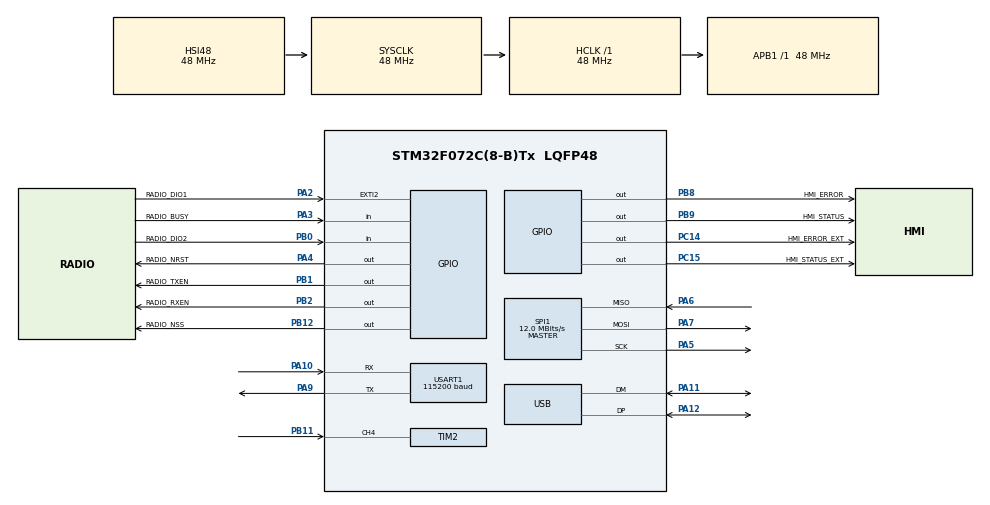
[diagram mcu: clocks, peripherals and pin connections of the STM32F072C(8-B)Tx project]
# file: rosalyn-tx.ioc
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Mcu.Family=STM32F0
Mcu.Name=STM32F072C(8-B)Tx
Mcu.Package=LQFP48
NVIC.EXTI2_3_IRQn=true\:0\:0\:false\:false\:true\:true\:true
NVIC.TIM2_IRQn=true\:0\:0\:false\:false\:true\:true\:true
NVIC.USB_IRQn=true\:0\:0\:false\:false\:true\:false\:true
PA10.GPIO_PuPd=GPIO_PULLUP
PA10.Mode=Asynchronous
PA10.Signal=USART1_RX
PA11.Mode=Device
PA11.Signal=USB_DM
PA12.Mode=Device
PA12.Signal=USB_DP
PA13.Mode=Serial_Wire
PA13.Signal=SYS_SWDIO
PA14.Mode=Serial_Wire
PA14.Signal=SYS_SWCLK
PA2.GPIO_Label=RADIO_DIO1
PA2.Signal=GPXTI2
PA3.GPIO_Label=RADIO_BUSY
PA3.Signal=GPIO_Input
PA4.GPIO_Label=RADIO_NRST
PA4.PinState=GPIO_PIN_SET
PA4.Signal=GPIO_Output
PA5.Mode=Full_Duplex_Master
PA5.Signal=SPI1_SCK
PA6.GPIO_PuPd=GPIO_PULLUP
PA6.Mode=Full_Duplex_Master
PA6.Signal=SPI1_MISO
PA7.Mode=Full_Duplex_Master
PA7.Signal=SPI1_MOSI
PA9.Mode=Asynchronous
PA9.Signal=USART1_TX
PB0.GPIO_Label=RADIO_DIO2
PB0.Signal=GPIO_Input
PB1.GPIO_Label=RADIO_TXEN
PB1.Signal=GPIO_Output
PB11.GPIO_ModeDefaultPP=GPIO_MODE_AF_PP
PB11.Signal=S_TIM2_CH4
PB12.GPIO_Label=RADIO_NSS
PB12.PinState=GPIO_PIN_SET
PB12.Signal=GPIO_Output
PB2.GPIO_Label=RADIO_RXEN
PB2.Signal=GPIO_Output
PB8.GPIO_Label=HMI_ERROR
PB8.PinState=GPIO_PIN_SET
PB8.Signal=GPIO_Output
PB9.GPIO_Label=HMI_STATUS
PB9.PinState=GPIO_PIN_SET
PB9.Signal=GPIO_Output
PC14-OSC32_IN.GPIO_Label=HMI_ERROR_EXT
PC14-OSC32_IN.PinState=GPIO_PIN_SET
PC14-OSC32_IN.Signal=GPIO_Output
PC15-OSC32_OUT.GPIO_Label=HMI_STATUS_EXT
PC15-OSC32_OUT.PinState=GPIO_PIN_SET
PC15-OSC32_OUT.Signal=GPIO_Output
ProjectManager.HeapSize=0x200
ProjectManager.StackSize=0x400
ProjectManager.TargetToolchain=STM32CubeIDE
RCC.AHBFreq_Value=48000000
RCC.APB1Freq_Value=48000000
RCC.APB1TimFreq_Value=48000000
RCC.HCLKFreq_Value=48000000
RCC.SYSCLKFreq_VALUE=48000000
RCC.SYSCLKSource=RCC_SYSCLKSOURCE_HSI48
SH.S_TIM2_CH4.0=TIM2_CH4,Input_Capture4_from_TI4
SPI1.BaudRatePrescaler=SPI_BAUDRATEPRESCALER_4
SPI1.CalculateBaudRate=12.0 MBits/s
SPI1.DataSize=SPI_DATASIZE_8BIT
SPI1.Direction=SPI_DIRECTION_2LINES
SPI1.Mode=SPI_MODE_MASTER
SPI1.VirtualType=VM_MASTER
TIM2.Channel-Input_Capture4_from_TI4=TIM_CHANNEL_4
TIM2.ICPolarity_CH4=TIM_INPUTCHANNELPOLARITY_FALLING
TIM2.Prescaler=0
USART1.BaudRate=115200
USART1.VirtualMode-Asynchronous=VM_ASYNC
USB_DEVICE.CLASS_NAME_FS=CDC
USB_DEVICE.VirtualMode=Cdc
USB_DEVICE.VirtualModeFS=Cdc_FS
VP_CRC_VS_CRC.Mode=CRC_Activate
VP_RCC_USB.Mode=CRS SYNC Source USB
VP_USB_DEVICE_VS_USB_DEVICE_CDC_FS.Mode=CDC_FS
board=custom

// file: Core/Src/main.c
/* USER CODE BEGIN Header */
/**
  ******************************************************************************
  * @file           : main.c
  * @brief          : Main program body
  ******************************************************************************
  * @attention
  *
  * <h2><center>&copy; Copyright (c) 2020 STMicroelectronics.
  * All rights reserved.</center></h2>
  *
  * This software component is licensed by ST under BSD 3-Clause license,
  * the "License"; You may not use this file except in compliance with the
  * License. You may obtain a copy of the License at:
  *                        opensource.org/licenses/BSD-3-Clause
  *
  ******************************************************************************
  */
/* USER CODE END Header */
#include "main.h"
#include "usb_device.h"

CRC_HandleTypeDef hcrc;

SPI_HandleTypeDef hspi1;

TIM_HandleTypeDef htim2;

void SystemClock_Config(void);
static void MX_GPIO_Init(void);
static void MX_SPI1_Init(void);
static void MX_USART1_UART_Init(void);
static void MX_TIM2_Init(void);
static void MX_CRC_Init(void);

int main(void)
{

  /* MCU Configuration--------------------------------------------------------*/

  /* Reset of all peripherals, Initializes the Flash interface and the Systick. */
  HAL_Init();

  /* Configure the system clock */
  SystemClock_Config();

  /* Initialize all configured peripherals */
  MX_GPIO_Init();
  MX_SPI1_Init();
  MX_USART1_UART_Init();
  MX_USB_DEVICE_Init();
  MX_TIM2_Init();
  MX_CRC_Init();
  /* USER CODE BEGIN 2 */
  extern void RosalynTxSetup( void );
  RosalynTxSetup();
  /* USER CODE END 2 */

  /* Infinite loop */
  while (1)
  {

    /* USER CODE BEGIN 3 */
    extern void RosalynTxLoop( void );
    RosalynTxLoop();
  }
  /* USER CODE END 3 */
}

void SystemClock_Config(void)
{
  RCC_OscInitTypeDef RCC_OscInitStruct = {0};
  RCC_ClkInitTypeDef RCC_ClkInitStruct = {0};
  RCC_PeriphCLKInitTypeDef PeriphClkInit = {0};
  RCC_CRSInitTypeDef RCC_CRSInitStruct = {0};

  /** Initializes the RCC Oscillators according to the specified parameters
  * in the RCC_OscInitTypeDef structure.
  */
  RCC_OscInitStruct.OscillatorType = RCC_OSCILLATORTYPE_HSI48;
  RCC_OscInitStruct.HSI48State = RCC_HSI48_ON;
  RCC_OscInitStruct.PLL.PLLState = RCC_PLL_NONE;
  if (HAL_RCC_OscConfig(&RCC_OscInitStruct) != HAL_OK)
  {
    Error_Handler();
  }
  /** Initializes the CPU, AHB and APB buses clocks
  */
  RCC_ClkInitStruct.ClockType = RCC_CLOCKTYPE_HCLK|RCC_CLOCKTYPE_SYSCLK
                              |RCC_CLOCKTYPE_PCLK1;
  RCC_ClkInitStruct.SYSCLKSource = RCC_SYSCLKSOURCE_HSI48;
  RCC_ClkInitStruct.AHBCLKDivider = RCC_SYSCLK_DIV1;
  RCC_ClkInitStruct.APB1CLKDivider = RCC_HCLK_DIV1;

  if (HAL_RCC_ClockConfig(&RCC_ClkInitStruct, FLASH_LATENCY_1) != HAL_OK)
  {
    Error_Handler();
  }
  PeriphClkInit.PeriphClockSelection = RCC_PERIPHCLK_USB|RCC_PERIPHCLK_USART1;
  PeriphClkInit.Usart1ClockSelection = RCC_USART1CLKSOURCE_PCLK1;
  PeriphClkInit.UsbClockSelection = RCC_USBCLKSOURCE_HSI48;

  if (HAL_RCCEx_PeriphCLKConfig(&PeriphClkInit) != HAL_OK)
  {
    Error_Handler();
  }
  /** Enable the SYSCFG APB clock
  */
  __HAL_RCC_CRS_CLK_ENABLE();
  /** Configures CRS
  */
  RCC_CRSInitStruct.Prescaler = RCC_CRS_SYNC_DIV1;
  RCC_CRSInitStruct.Source = RCC_CRS_SYNC_SOURCE_USB;
  RCC_CRSInitStruct.Polarity = RCC_CRS_SYNC_POLARITY_RISING;
  RCC_CRSInitStruct.ReloadValue = __HAL_RCC_CRS_RELOADVALUE_CALCULATE(48000000,1000);
  RCC_CRSInitStruct.ErrorLimitValue = 34;
  RCC_CRSInitStruct.HSI48CalibrationValue = 32;

  HAL_RCCEx_CRSConfig(&RCC_CRSInitStruct);
}

static void MX_CRC_Init(void)
{

  hcrc.Instance = CRC;
  hcrc.Init.DefaultPolynomialUse = DEFAULT_POLYNOMIAL_ENABLE;
  hcrc.Init.DefaultInitValueUse = DEFAULT_INIT_VALUE_ENABLE;
  hcrc.Init.InputDataInversionMode = CRC_INPUTDATA_INVERSION_NONE;
  hcrc.Init.OutputDataInversionMode = CRC_OUTPUTDATA_INVERSION_DISABLE;
  hcrc.InputDataFormat = CRC_INPUTDATA_FORMAT_BYTES;
  if (HAL_CRC_Init(&hcrc) != HAL_OK)
  {
    Error_Handler();
  }

}

static void MX_SPI1_Init(void)
{

  /* SPI1 parameter configuration*/
  hspi1.Instance = SPI1;
  hspi1.Init.Mode = SPI_MODE_MASTER;
  hspi1.Init.Direction = SPI_DIRECTION_2LINES;
  hspi1.Init.DataSize = SPI_DATASIZE_8BIT;
  hspi1.Init.CLKPolarity = SPI_POLARITY_LOW;
  hspi1.Init.CLKPhase = SPI_PHASE_1EDGE;
  hspi1.Init.NSS = SPI_NSS_SOFT;
  hspi1.Init.BaudRatePrescaler = SPI_BAUDRATEPRESCALER_4;
  hspi1.Init.FirstBit = SPI_FIRSTBIT_MSB;
  hspi1.Init.TIMode = SPI_TIMODE_DISABLE;
  hspi1.Init.CRCCalculation = SPI_CRCCALCULATION_DISABLE;
  hspi1.Init.CRCPolynomial = 7;
  hspi1.Init.CRCLength = SPI_CRC_LENGTH_DATASIZE;
  hspi1.Init.NSSPMode = SPI_NSS_PULSE_ENABLE;
  if (HAL_SPI_Init(&hspi1) != HAL_OK)
  {
    Error_Handler();
  }

}

static void MX_TIM2_Init(void)
{

  TIM_MasterConfigTypeDef sMasterConfig = {0};
  TIM_IC_InitTypeDef sConfigIC = {0};

  htim2.Instance = TIM2;
  htim2.Init.Prescaler = 0;
  htim2.Init.CounterMode = TIM_COUNTERMODE_UP;
  htim2.Init.Period = 4294967295;
  htim2.Init.ClockDivision = TIM_CLOCKDIVISION_DIV1;
  htim2.Init.AutoReloadPreload = TIM_AUTORELOAD_PRELOAD_DISABLE;
  if (HAL_TIM_IC_Init(&htim2) != HAL_OK)
  {
    Error_Handler();
  }
  sMasterConfig.MasterOutputTrigger = TIM_TRGO_RESET;
  sMasterConfig.MasterSlaveMode = TIM_MASTERSLAVEMODE_DISABLE;
  if (HAL_TIMEx_MasterConfigSynchronization(&htim2, &sMasterConfig) != HAL_OK)
  {
    Error_Handler();
  }
  sConfigIC.ICPolarity = TIM_INPUTCHANNELPOLARITY_FALLING;
  sConfigIC.ICSelection = TIM_ICSELECTION_DIRECTTI;
  sConfigIC.ICPrescaler = TIM_ICPSC_DIV1;
  sConfigIC.ICFilter = 0;
  if (HAL_TIM_IC_ConfigChannel(&htim2, &sConfigIC, TIM_CHANNEL_4) != HAL_OK)
  {
    Error_Handler();
  }
  /* USER CODE BEGIN TIM2_Init 2 */
  if(HAL_TIM_IC_Start_IT(&htim2, TIM_CHANNEL_3) != HAL_OK)
  {
    Error_Handler();
  }
  if(HAL_TIM_IC_Start_IT(&htim2, TIM_CHANNEL_4) != HAL_OK)
  {
    Error_Handler();
  }
  /* USER CODE END TIM2_Init 2 */

}

static void MX_USART1_UART_Init(void)
{

  LL_USART_InitTypeDef USART_InitStruct = {0};

  LL_GPIO_InitTypeDef GPIO_InitStruct = {0};

  /* Peripheral clock enable */
  LL_APB1_GRP2_EnableClock(LL_APB1_GRP2_PERIPH_USART1);

  LL_AHB1_GRP1_EnableClock(LL_AHB1_GRP1_PERIPH_GPIOA);
  /**USART1 GPIO Configuration
  PA9   ------> USART1_TX
  PA10   ------> USART1_RX
  */
  GPIO_InitStruct.Pin = LL_GPIO_PIN_9;
  GPIO_InitStruct.Mode = LL_GPIO_MODE_ALTERNATE;
  GPIO_InitStruct.Speed = LL_GPIO_SPEED_FREQ_HIGH;
  GPIO_InitStruct.OutputType = LL_GPIO_OUTPUT_PUSHPULL;
  GPIO_InitStruct.Pull = LL_GPIO_PULL_NO;
  GPIO_InitStruct.Alternate = LL_GPIO_AF_1;
  LL_GPIO_Init(GPIOA, &GPIO_InitStruct);

  GPIO_InitStruct.Pin = LL_GPIO_PIN_10;
  GPIO_InitStruct.Mode = LL_GPIO_MODE_ALTERNATE;
  GPIO_InitStruct.Speed = LL_GPIO_SPEED_FREQ_HIGH;
  GPIO_InitStruct.OutputType = LL_GPIO_OUTPUT_PUSHPULL;
  GPIO_InitStruct.Pull = LL_GPIO_PULL_UP;
  GPIO_InitStruct.Alternate = LL_GPIO_AF_1;
  LL_GPIO_Init(GPIOA, &GPIO_InitStruct);

  USART_InitStruct.BaudRate = 115200;
  USART_InitStruct.DataWidth = LL_USART_DATAWIDTH_8B;
  USART_InitStruct.StopBits = LL_USART_STOPBITS_1;
  USART_InitStruct.Parity = LL_USART_PARITY_NONE;
  USART_InitStruct.TransferDirection = LL_USART_DIRECTION_TX_RX;
  USART_InitStruct.HardwareFlowControl = LL_USART_HWCONTROL_NONE;
  USART_InitStruct.OverSampling = LL_USART_OVERSAMPLING_16;
  LL_USART_Init(USART1, &USART_InitStruct);
  LL_USART_DisableIT_CTS(USART1);
  LL_USART_ConfigAsyncMode(USART1);
  LL_USART_Enable(USART1);

}

static void MX_GPIO_Init(void)
{
  GPIO_InitTypeDef GPIO_InitStruct = {0};

  /* GPIO Ports Clock Enable */
  __HAL_RCC_GPIOC_CLK_ENABLE();
  __HAL_RCC_GPIOF_CLK_ENABLE();
  __HAL_RCC_GPIOA_CLK_ENABLE();
  __HAL_RCC_GPIOB_CLK_ENABLE();

  /*Configure GPIO pin Output Level */
  HAL_GPIO_WritePin(GPIOC, HMI_ERROR_EXT_Pin|HMI_STATUS_EXT_Pin, GPIO_PIN_SET);

  /*Configure GPIO pin Output Level */
  HAL_GPIO_WritePin(RADIO_NRST_GPIO_Port, RADIO_NRST_Pin, GPIO_PIN_SET);

  /*Configure GPIO pin Output Level */
  HAL_GPIO_WritePin(GPIOB, RADIO_TXEN_Pin|RADIO_RXEN_Pin, GPIO_PIN_RESET);

  /*Configure GPIO pin Output Level */
  HAL_GPIO_WritePin(GPIOB, RADIO_NSS_Pin|HMI_ERROR_Pin|HMI_STATUS_Pin, GPIO_PIN_SET);

  /*Configure GPIO pin : PC13 */
  GPIO_InitStruct.Pin = GPIO_PIN_13;
  GPIO_InitStruct.Mode = GPIO_MODE_ANALOG;
  GPIO_InitStruct.Pull = GPIO_NOPULL;
  HAL_GPIO_Init(GPIOC, &GPIO_InitStruct);

  /*Configure GPIO pins : HMI_ERROR_EXT_Pin HMI_STATUS_EXT_Pin */
  GPIO_InitStruct.Pin = HMI_ERROR_EXT_Pin|HMI_STATUS_EXT_Pin;
  GPIO_InitStruct.Mode = GPIO_MODE_OUTPUT_PP;
  GPIO_InitStruct.Pull = GPIO_NOPULL;
  GPIO_InitStruct.Speed = GPIO_SPEED_FREQ_LOW;
  HAL_GPIO_Init(GPIOC, &GPIO_InitStruct);

  /*Configure GPIO pins : PF0 PF1 */
  GPIO_InitStruct.Pin = GPIO_PIN_0|GPIO_PIN_1;
  GPIO_InitStruct.Mode = GPIO_MODE_ANALOG;
  GPIO_InitStruct.Pull = GPIO_NOPULL;
  HAL_GPIO_Init(GPIOF, &GPIO_InitStruct);

  /*Configure GPIO pins : PA0 PA1 PA8 PA15 */
  GPIO_InitStruct.Pin = GPIO_PIN_0|GPIO_PIN_1|GPIO_PIN_8|GPIO_PIN_15;
  GPIO_InitStruct.Mode = GPIO_MODE_ANALOG;
  GPIO_InitStruct.Pull = GPIO_NOPULL;
  HAL_GPIO_Init(GPIOA, &GPIO_InitStruct);

  /*Configure GPIO pin : RADIO_DIO1_Pin */
  GPIO_InitStruct.Pin = RADIO_DIO1_Pin;
  GPIO_InitStruct.Mode = GPIO_MODE_IT_RISING;
  GPIO_InitStruct.Pull = GPIO_NOPULL;
  HAL_GPIO_Init(RADIO_DIO1_GPIO_Port, &GPIO_InitStruct);

  /*Configure GPIO pin : RADIO_BUSY_Pin */
  GPIO_InitStruct.Pin = RADIO_BUSY_Pin;
  GPIO_InitStruct.Mode = GPIO_MODE_INPUT;
  GPIO_InitStruct.Pull = GPIO_NOPULL;
  HAL_GPIO_Init(RADIO_BUSY_GPIO_Port, &GPIO_InitStruct);

  /*Configure GPIO pin : RADIO_NRST_Pin */
  GPIO_InitStruct.Pin = RADIO_NRST_Pin;
  GPIO_InitStruct.Mode = GPIO_MODE_OUTPUT_PP;
  GPIO_InitStruct.Pull = GPIO_NOPULL;
  GPIO_InitStruct.Speed = GPIO_SPEED_FREQ_LOW;
  HAL_GPIO_Init(RADIO_NRST_GPIO_Port, &GPIO_InitStruct);

  /*Configure GPIO pin : RADIO_DIO2_Pin */
  GPIO_InitStruct.Pin = RADIO_DIO2_Pin;
  GPIO_InitStruct.Mode = GPIO_MODE_INPUT;
  GPIO_InitStruct.Pull = GPIO_NOPULL;
  HAL_GPIO_Init(RADIO_DIO2_GPIO_Port, &GPIO_InitStruct);

  /*Configure GPIO pins : RADIO_TXEN_Pin RADIO_RXEN_Pin RADIO_NSS_Pin HMI_ERROR_Pin
                           HMI_STATUS_Pin */
  GPIO_InitStruct.Pin = RADIO_TXEN_Pin|RADIO_RXEN_Pin|RADIO_NSS_Pin|HMI_ERROR_Pin
                          |HMI_STATUS_Pin;
  GPIO_InitStruct.Mode = GPIO_MODE_OUTPUT_PP;
  GPIO_InitStruct.Pull = GPIO_NOPULL;
  GPIO_InitStruct.Speed = GPIO_SPEED_FREQ_LOW;
  HAL_GPIO_Init(GPIOB, &GPIO_InitStruct);

  /*Configure GPIO pins : PB10 PB13 PB14 PB15
                           PB3 PB4 PB5 PB6
                           PB7 */
  GPIO_InitStruct.Pin = GPIO_PIN_10|GPIO_PIN_13|GPIO_PIN_14|GPIO_PIN_15
                          |GPIO_PIN_3|GPIO_PIN_4|GPIO_PIN_5|GPIO_PIN_6
                          |GPIO_PIN_7;
  GPIO_InitStruct.Mode = GPIO_MODE_ANALOG;
  GPIO_InitStruct.Pull = GPIO_NOPULL;
  HAL_GPIO_Init(GPIOB, &GPIO_InitStruct);

  /* EXTI interrupt init*/
  HAL_NVIC_SetPriority(EXTI2_3_IRQn, 0, 0);
  HAL_NVIC_EnableIRQ(EXTI2_3_IRQn);

}

void Error_Handler(void)
{
}

/************************ (C) COPYRIGHT STMicroelectronics *****END OF FILE****/
